# CBASS0_FW register map
Vendor: Texas Instruments
Peripheral module from a debugger description file (folder am243x).
Registers are 32-bit, read-write, reset 0x0 unless marked. A register's access mark holds for its fields unless they carry their own. Offsets are as the file gives them; lines under a group give offsets from that group; [hi:lo] are bit positions; {n}, {i} and the like mark numbered series; 'fields as' and 'values as' point back to an identical list; <NAME> marks a mode.

## CBASS0_FW
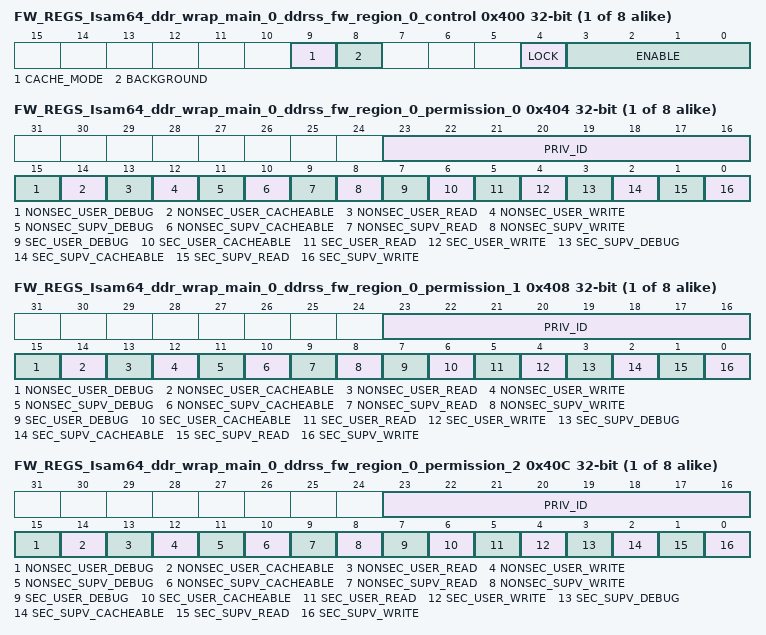
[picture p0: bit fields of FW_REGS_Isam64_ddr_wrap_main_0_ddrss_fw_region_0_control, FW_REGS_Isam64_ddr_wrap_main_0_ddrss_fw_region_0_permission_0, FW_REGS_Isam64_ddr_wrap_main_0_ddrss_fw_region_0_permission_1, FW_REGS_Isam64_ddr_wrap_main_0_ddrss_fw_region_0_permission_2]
{0x400+0x20*i} FW_REGS_Isam64_ddr_wrap_main_0_ddrss_fw_region_{i}_control access not given (i=0..7) — The FW Region {i} Control Register defines the control fields for the slave Isam64_ddr_wrap_main_0.ddrss region {i} firewall.
  [9] CACHE_MODE rw — Cache mode for region. Set to 1 to check cache permissions. Set to 0 to ignore cache permissions.
  [8] BACKGROUND rw — Background enable for region. There can be 1 backgroun region per FW and foreground regions can have overlapping addresses only with the background region.
  [4] LOCK — Lock region. Once set region values cannot be modified. (access R/W1TS)
  [3:0] ENABLE rw — Enable region. A value of 0xA enables, others disable.
{0x404+0x20*i} FW_REGS_Isam64_ddr_wrap_main_0_ddrss_fw_region_{i}_permission_0 (i=0..7) — The FW Region {i} Permission 0 Register defines the permissions for the slave Isam64_ddr_wrap_main_0.ddrss region {i} firewall.
  [23:16] PRIV_ID — Allowed privid.
  [15] NONSEC_USER_DEBUG — Non-secure user debug allowed.
  [14] NONSEC_USER_CACHEABLE — Non-secure user cacheable allowed.
  [13] NONSEC_USER_READ — Non-secure user read allowed.
  [12] NONSEC_USER_WRITE — Non-secure user write allowed.
  [11] NONSEC_SUPV_DEBUG — Non-secure supervisor debug allowed.
  [10] NONSEC_SUPV_CACHEABLE — Non-secure supervisor cacheable allowed.
  [9] NONSEC_SUPV_READ — Non-secure supervisor read allowed.
  [8] NONSEC_SUPV_WRITE — Non-secure supervisor write allowed.
  [7] SEC_USER_DEBUG — Secure user debug allowed.
  [6] SEC_USER_CACHEABLE — Secure user cacheable allowed.
  [5] SEC_USER_READ — Secure user read allowed.
  [4] SEC_USER_WRITE — Secure user write allowed.
  [3] SEC_SUPV_DEBUG — Secure supervisor debug allowed.
  [2] SEC_SUPV_CACHEABLE — Secure supervisor cacheable allowed.
  [1] SEC_SUPV_READ — Secure supervisor read allowed.
  [0] SEC_SUPV_WRITE — Secure supervisor write allowed.
{0x408+0x20*i} FW_REGS_Isam64_ddr_wrap_main_0_ddrss_fw_region_{i}_permission_1 (i=0..7) — The FW Region {i} Permission 1 Register defines the permissions for the slave Isam64_ddr_wrap_main_0.ddrss region {i} firewall.
  fields as FW_REGS_Isam64_ddr_wrap_main_0_ddrss_fw_region_0_permission_0
{0x40C+0x20*i} FW_REGS_Isam64_ddr_wrap_main_0_ddrss_fw_region_{i}_permission_2 (i=0..7) — The FW Region {i} Permission 2 Register defines the permissions for the slave Isam64_ddr_wrap_main_0.ddrss region {i} firewall.
  fields as FW_REGS_Isam64_ddr_wrap_main_0_ddrss_fw_region_0_permission_0
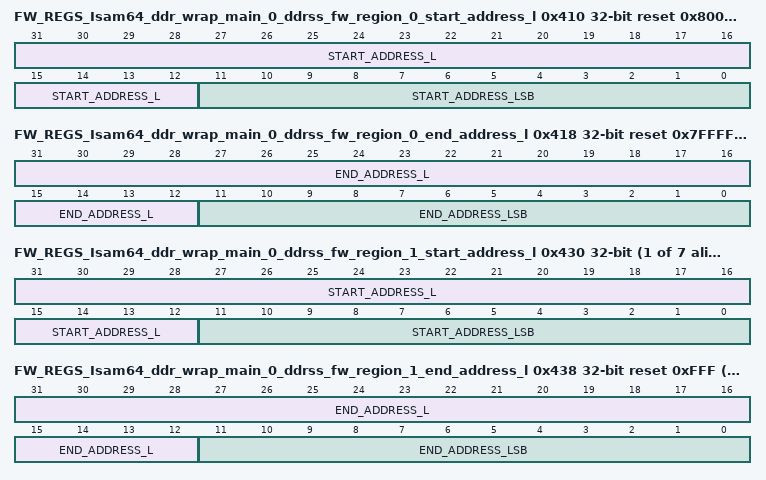
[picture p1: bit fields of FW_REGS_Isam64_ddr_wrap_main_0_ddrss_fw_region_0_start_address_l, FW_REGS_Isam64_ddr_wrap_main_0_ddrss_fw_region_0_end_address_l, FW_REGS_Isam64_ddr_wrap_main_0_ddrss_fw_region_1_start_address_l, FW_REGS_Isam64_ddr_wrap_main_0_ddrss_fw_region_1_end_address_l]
0x410 FW_REGS_Isam64_ddr_wrap_main_0_ddrss_fw_region_0_start_address_l access per field reset 0x80000000 — The FW Region 0 Start Address Low Register defines the start address bits 31 to 0 for the slave Isam64_ddr_wrap_main_0.ddrss region 0 firewall.
  [31:12] START_ADDRESS_L rw — Start address bits 31 to 12. Lowest 12 bits are forced to 0 as address must be 4KB aligned.
  [11:0] START_ADDRESS_LSB ro — Start address bits 11 to 0 are forced to 0 as address must be 4KB aligned.
{0x414+0x20*i} FW_REGS_Isam64_ddr_wrap_main_0_ddrss_fw_region_{i}_start_address_h (i=0..7) — The FW Region {i} Start Address High Register defines the start address bits 47 to 32 for the slave Isam64_ddr_wrap_main_0.ddrss region {i} firewall.
  [15:0] START_ADDRESS_H — Start address bits 47 to 32.
0x418 FW_REGS_Isam64_ddr_wrap_main_0_ddrss_fw_region_0_end_address_l access per field reset 0x7FFFFFFF — The FW Region 0 End Address Low Register defines the end address bits 31 to 0 to include for the slave Isam64_ddr_wrap_main_0.ddrss region 0 firewall.
  [31:12] END_ADDRESS_L rw — End address bits 31 to 12 to include in the match. Lowest 12 bits are forced to 1s as address must be 4KB aligned.
  [11:0] END_ADDRESS_LSB ro — End address bits 11 to 0 are forced to 1s as address must be 4KB aligned minus 1.
0x41C FW_REGS_Isam64_ddr_wrap_main_0_ddrss_fw_region_0_end_address_h reset 0x2 — The FW Region 0 End Address High Register defines the end address bits 47 to 32 to include for the slave Isam64_ddr_wrap_main_0.ddrss region 0 firewall.
  [15:0] END_ADDRESS_H — End address bits 47 to 32 to include in the match.
{0x410+0x20*i} FW_REGS_Isam64_ddr_wrap_main_0_ddrss_fw_region_{i}_start_address_l access per field (i=1..7) — The FW Region {i} Start Address Low Register defines the start address bits 31 to 0 for the slave Isam64_ddr_wrap_main_0.ddrss region {i} firewall.
  fields as FW_REGS_Isam64_ddr_wrap_main_0_ddrss_fw_region_0_start_address_l
{0x418+0x20*i} FW_REGS_Isam64_ddr_wrap_main_0_ddrss_fw_region_{i}_end_address_l access per field reset 0xFFF (i=1..7) — The FW Region {i} End Address Low Register defines the end address bits 31 to 0 to include for the slave Isam64_ddr_wrap_main_0.ddrss region {i} firewall.
  fields as FW_REGS_Isam64_ddr_wrap_main_0_ddrss_fw_region_0_end_address_l
{0x41C+0x20*i} FW_REGS_Isam64_ddr_wrap_main_0_ddrss_fw_region_{i}_end_address_h (i=1..7) — The FW Region {i} End Address High Register defines the end address bits 47 to 32 to include for the slave Isam64_ddr_wrap_main_0.ddrss region {i} firewall.
  fields as FW_REGS_Isam64_ddr_wrap_main_0_ddrss_fw_region_0_end_address_h
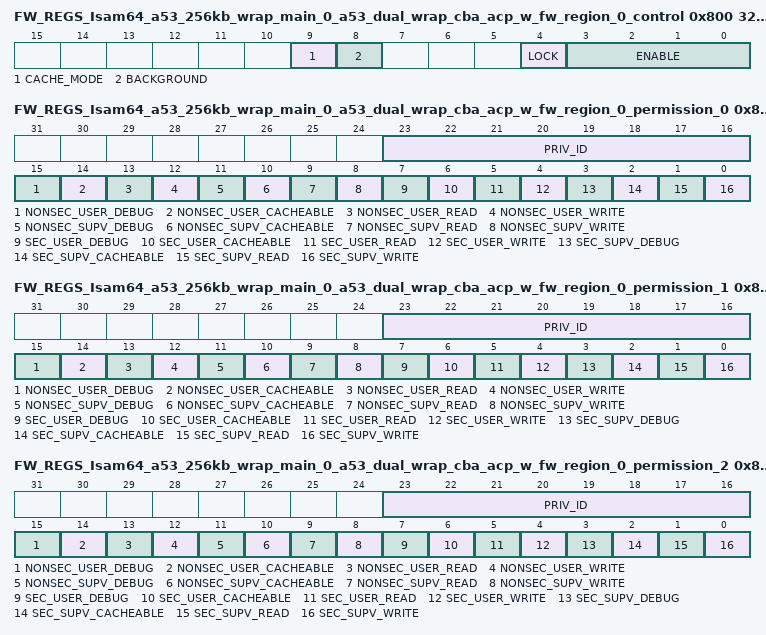
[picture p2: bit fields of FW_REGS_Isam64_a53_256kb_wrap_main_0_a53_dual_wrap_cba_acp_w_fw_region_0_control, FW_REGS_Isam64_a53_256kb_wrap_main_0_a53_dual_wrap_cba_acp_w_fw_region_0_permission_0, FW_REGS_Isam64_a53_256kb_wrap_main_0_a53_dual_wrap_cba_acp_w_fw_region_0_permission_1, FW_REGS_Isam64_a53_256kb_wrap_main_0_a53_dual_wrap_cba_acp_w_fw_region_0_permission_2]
{0x800+0x20*i} FW_REGS_Isam64_a53_256kb_wrap_main_0_a53_dual_wrap_cba_acp_w_fw_region_{i}_control access not given (i=0..7) — The FW Region {i} Control Register defines the control fields for the slave Isam64_a53_256kb_wrap_main_0.a53_dual_wrap_cba_acp_w region {i} firewall.
  fields as FW_REGS_Isam64_ddr_wrap_main_0_ddrss_fw_region_0_control
{0x804+0x20*i} FW_REGS_Isam64_a53_256kb_wrap_main_0_a53_dual_wrap_cba_acp_w_fw_region_{i}_permission_0 (i=0..7) — The FW Region {i} Permission 0 Register defines the permissions for the slave Isam64_a53_256kb_wrap_main_0.a53_dual_wrap_cba_acp_w region {i} firewall.
  fields as FW_REGS_Isam64_ddr_wrap_main_0_ddrss_fw_region_0_permission_0
{0x808+0x20*i} FW_REGS_Isam64_a53_256kb_wrap_main_0_a53_dual_wrap_cba_acp_w_fw_region_{i}_permission_1 (i=0..7) — The FW Region {i} Permission 1 Register defines the permissions for the slave Isam64_a53_256kb_wrap_main_0.a53_dual_wrap_cba_acp_w region {i} firewall.
  fields as FW_REGS_Isam64_ddr_wrap_main_0_ddrss_fw_region_0_permission_0
{0x80C+0x20*i} FW_REGS_Isam64_a53_256kb_wrap_main_0_a53_dual_wrap_cba_acp_w_fw_region_{i}_permission_2 (i=0..7) — The FW Region {i} Permission 2 Register defines the permissions for the slave Isam64_a53_256kb_wrap_main_0.a53_dual_wrap_cba_acp_w region {i} firewall.
  fields as FW_REGS_Isam64_ddr_wrap_main_0_ddrss_fw_region_0_permission_0
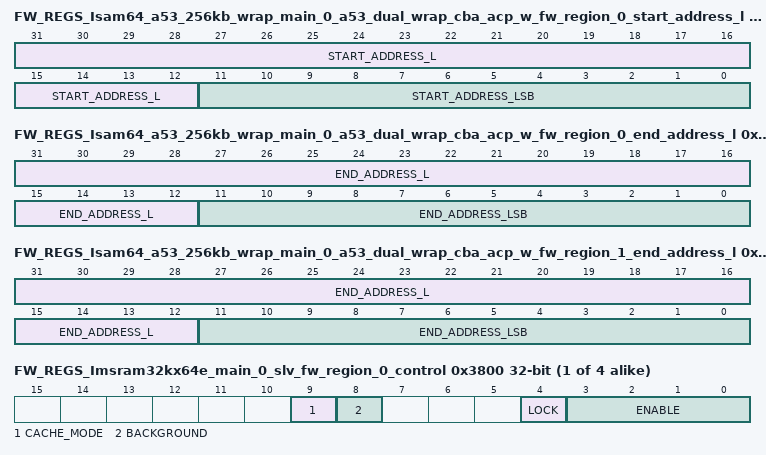
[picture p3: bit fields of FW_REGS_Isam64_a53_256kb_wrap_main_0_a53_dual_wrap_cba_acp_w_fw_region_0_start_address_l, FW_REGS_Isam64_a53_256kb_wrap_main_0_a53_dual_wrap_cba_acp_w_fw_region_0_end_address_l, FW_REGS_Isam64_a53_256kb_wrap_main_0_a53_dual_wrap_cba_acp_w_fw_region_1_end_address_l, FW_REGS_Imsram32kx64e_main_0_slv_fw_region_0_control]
{0x810+0x20*i} FW_REGS_Isam64_a53_256kb_wrap_main_0_a53_dual_wrap_cba_acp_w_fw_region_{i}_start_address_l access per field (i=0..7) — The FW Region {i} Start Address Low Register defines the start address bits 31 to 0 for the slave Isam64_a53_256kb_wrap_main_0.a53_dual_wrap_cba_acp_w region {i} firewall.
  fields as FW_REGS_Isam64_ddr_wrap_main_0_ddrss_fw_region_0_start_address_l
{0x814+0x20*i} FW_REGS_Isam64_a53_256kb_wrap_main_0_a53_dual_wrap_cba_acp_w_fw_region_{i}_start_address_h (i=0..7) — The FW Region {i} Start Address High Register defines the start address bits 47 to 32 for the slave Isam64_a53_256kb_wrap_main_0.a53_dual_wrap_cba_acp_w region {i} firewall.
  [15:0] START_ADDRESS_H — Start address bits 47 to 32.
0x818 FW_REGS_Isam64_a53_256kb_wrap_main_0_a53_dual_wrap_cba_acp_w_fw_region_0_end_address_l access per field reset 0xFFFFFFFF — The FW Region 0 End Address Low Register defines the end address bits 31 to 0 to include for the slave Isam64_a53_256kb_wrap_main_0.a53_dual_wrap_cba_acp_w region 0 firewall.
  fields as FW_REGS_Isam64_ddr_wrap_main_0_ddrss_fw_region_0_end_address_l
0x81C FW_REGS_Isam64_a53_256kb_wrap_main_0_a53_dual_wrap_cba_acp_w_fw_region_0_end_address_h reset 0xF — The FW Region 0 End Address High Register defines the end address bits 47 to 32 to include for the slave Isam64_a53_256kb_wrap_main_0.a53_dual_wrap_cba_acp_w region 0 firewall.
  fields as FW_REGS_Isam64_ddr_wrap_main_0_ddrss_fw_region_0_end_address_h
{0x818+0x20*i} FW_REGS_Isam64_a53_256kb_wrap_main_0_a53_dual_wrap_cba_acp_w_fw_region_{i}_end_address_l access per field reset 0xFFF (i=1..7) — The FW Region {i} End Address Low Register defines the end address bits 31 to 0 to include for the slave Isam64_a53_256kb_wrap_main_0.a53_dual_wrap_cba_acp_w region {i} firewall.
  fields as FW_REGS_Isam64_ddr_wrap_main_0_ddrss_fw_region_0_end_address_l
{0x81C+0x20*i} FW_REGS_Isam64_a53_256kb_wrap_main_0_a53_dual_wrap_cba_acp_w_fw_region_{i}_end_address_h (i=1..7) — The FW Region {i} End Address High Register defines the end address bits 47 to 32 to include for the slave Isam64_a53_256kb_wrap_main_0.a53_dual_wrap_cba_acp_w region {i} firewall.
  fields as FW_REGS_Isam64_ddr_wrap_main_0_ddrss_fw_region_0_end_address_h
{0x3800+0x20*i} FW_REGS_Imsram32kx64e_main_0_slv_fw_region_{i}_control access not given (i=0..3) — The FW Region {i} Control Register defines the control fields for the slave Imsram32kx64e_main_0.slv region {i} firewall.
  fields as FW_REGS_Isam64_ddr_wrap_main_0_ddrss_fw_region_0_control
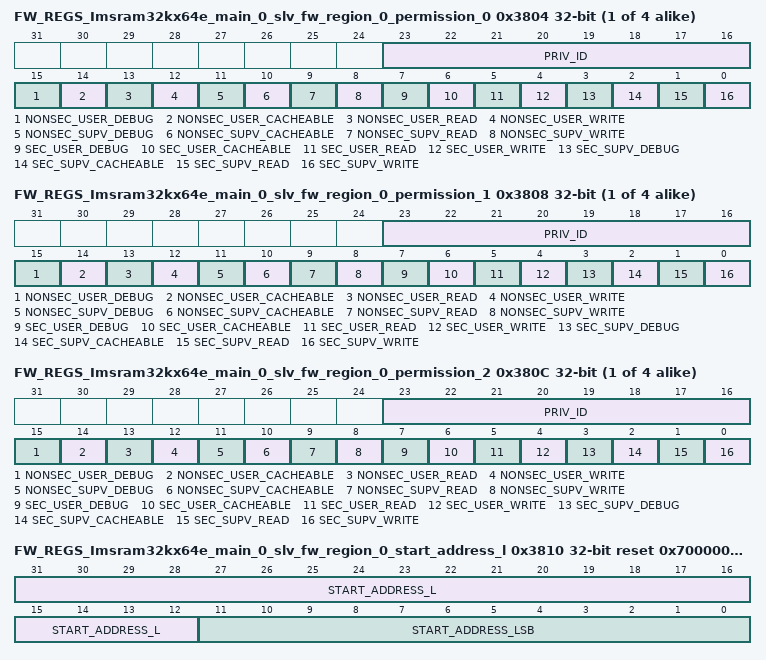
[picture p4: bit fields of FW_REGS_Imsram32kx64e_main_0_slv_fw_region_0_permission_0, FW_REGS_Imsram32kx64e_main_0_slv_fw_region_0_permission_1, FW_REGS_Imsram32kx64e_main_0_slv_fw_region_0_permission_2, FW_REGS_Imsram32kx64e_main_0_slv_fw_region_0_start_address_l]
{0x3804+0x20*i} FW_REGS_Imsram32kx64e_main_0_slv_fw_region_{i}_permission_0 (i=0..3) — The FW Region {i} Permission 0 Register defines the permissions for the slave Imsram32kx64e_main_0.slv region {i} firewall.
  fields as FW_REGS_Isam64_ddr_wrap_main_0_ddrss_fw_region_0_permission_0
{0x3808+0x20*i} FW_REGS_Imsram32kx64e_main_0_slv_fw_region_{i}_permission_1 (i=0..3) — The FW Region {i} Permission 1 Register defines the permissions for the slave Imsram32kx64e_main_0.slv region {i} firewall.
  fields as FW_REGS_Isam64_ddr_wrap_main_0_ddrss_fw_region_0_permission_0
{0x380C+0x20*i} FW_REGS_Imsram32kx64e_main_0_slv_fw_region_{i}_permission_2 (i=0..3) — The FW Region {i} Permission 2 Register defines the permissions for the slave Imsram32kx64e_main_0.slv region {i} firewall.
  fields as FW_REGS_Isam64_ddr_wrap_main_0_ddrss_fw_region_0_permission_0
0x3810 FW_REGS_Imsram32kx64e_main_0_slv_fw_region_0_start_address_l access per field reset 0x70000000 — The FW Region 0 Start Address Low Register defines the start address bits 31 to 0 for the slave Imsram32kx64e_main_0.slv region 0 firewall.
  fields as FW_REGS_Isam64_ddr_wrap_main_0_ddrss_fw_region_0_start_address_l
{0x3814+0x20*i} FW_REGS_Imsram32kx64e_main_0_slv_fw_region_{i}_start_address_h (i=0..3) — The FW Region {i} Start Address High Register defines the start address bits 47 to 32 for the slave Imsram32kx64e_main_0.slv region {i} firewall.
  [15:0] START_ADDRESS_H — Start address bits 47 to 32.
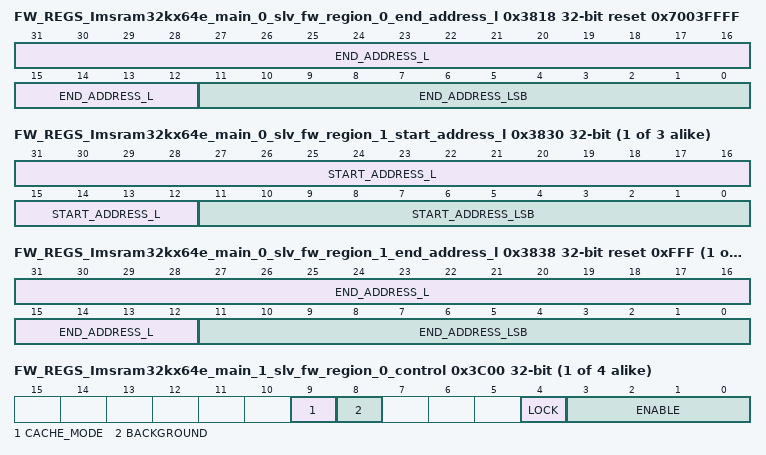
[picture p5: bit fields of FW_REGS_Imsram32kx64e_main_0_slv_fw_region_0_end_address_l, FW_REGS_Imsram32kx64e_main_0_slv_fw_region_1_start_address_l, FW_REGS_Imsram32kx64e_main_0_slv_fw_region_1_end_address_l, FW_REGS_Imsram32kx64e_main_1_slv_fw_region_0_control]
0x3818 FW_REGS_Imsram32kx64e_main_0_slv_fw_region_0_end_address_l access per field reset 0x7003FFFF — The FW Region 0 End Address Low Register defines the end address bits 31 to 0 to include for the slave Imsram32kx64e_main_0.slv region 0 firewall.
  fields as FW_REGS_Isam64_ddr_wrap_main_0_ddrss_fw_region_0_end_address_l
{0x381C+0x20*i} FW_REGS_Imsram32kx64e_main_0_slv_fw_region_{i}_end_address_h (i=0..3) — The FW Region {i} End Address High Register defines the end address bits 47 to 32 to include for the slave Imsram32kx64e_main_0.slv region {i} firewall.
  fields as FW_REGS_Isam64_ddr_wrap_main_0_ddrss_fw_region_0_end_address_h
{0x3810+0x20*i} FW_REGS_Imsram32kx64e_main_0_slv_fw_region_{i}_start_address_l access per field (i=1..3) — The FW Region {i} Start Address Low Register defines the start address bits 31 to 0 for the slave Imsram32kx64e_main_0.slv region {i} firewall.
  fields as FW_REGS_Isam64_ddr_wrap_main_0_ddrss_fw_region_0_start_address_l
{0x3818+0x20*i} FW_REGS_Imsram32kx64e_main_0_slv_fw_region_{i}_end_address_l access per field reset 0xFFF (i=1..3) — The FW Region {i} End Address Low Register defines the end address bits 31 to 0 to include for the slave Imsram32kx64e_main_0.slv region {i} firewall.
  fields as FW_REGS_Isam64_ddr_wrap_main_0_ddrss_fw_region_0_end_address_l
{0x3C00+0x20*i} FW_REGS_Imsram32kx64e_main_1_slv_fw_region_{i}_control access not given (i=0..3) — The FW Region {i} Control Register defines the control fields for the slave Imsram32kx64e_main_1.slv region {i} firewall.
  fields as FW_REGS_Isam64_ddr_wrap_main_0_ddrss_fw_region_0_control
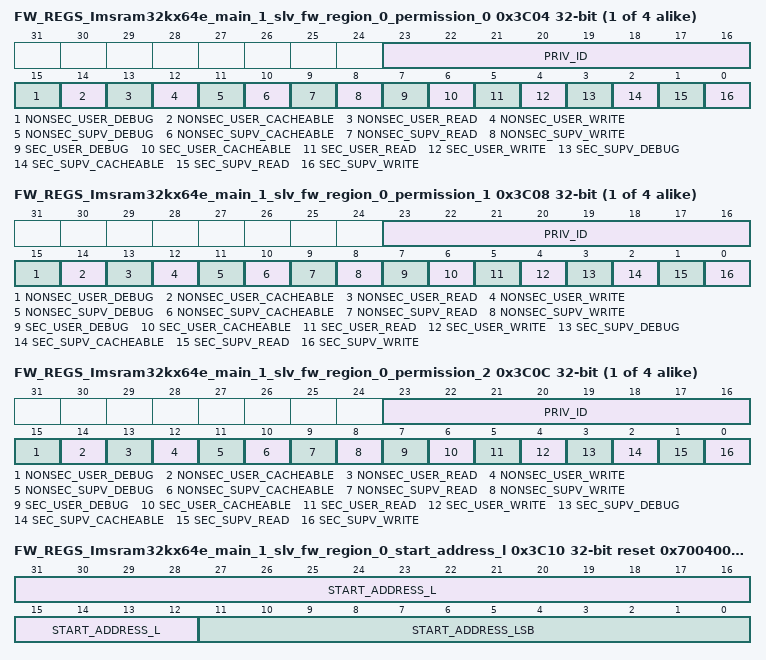
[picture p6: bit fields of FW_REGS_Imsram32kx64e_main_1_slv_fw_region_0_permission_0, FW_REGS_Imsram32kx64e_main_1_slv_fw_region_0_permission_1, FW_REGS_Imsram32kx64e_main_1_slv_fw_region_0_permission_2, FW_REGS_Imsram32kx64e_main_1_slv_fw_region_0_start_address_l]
{0x3C04+0x20*i} FW_REGS_Imsram32kx64e_main_1_slv_fw_region_{i}_permission_0 (i=0..3) — The FW Region {i} Permission 0 Register defines the permissions for the slave Imsram32kx64e_main_1.slv region {i} firewall.
  fields as FW_REGS_Isam64_ddr_wrap_main_0_ddrss_fw_region_0_permission_0
{0x3C08+0x20*i} FW_REGS_Imsram32kx64e_main_1_slv_fw_region_{i}_permission_1 (i=0..3) — The FW Region {i} Permission 1 Register defines the permissions for the slave Imsram32kx64e_main_1.slv region {i} firewall.
  fields as FW_REGS_Isam64_ddr_wrap_main_0_ddrss_fw_region_0_permission_0
{0x3C0C+0x20*i} FW_REGS_Imsram32kx64e_main_1_slv_fw_region_{i}_permission_2 (i=0..3) — The FW Region {i} Permission 2 Register defines the permissions for the slave Imsram32kx64e_main_1.slv region {i} firewall.
  fields as FW_REGS_Isam64_ddr_wrap_main_0_ddrss_fw_region_0_permission_0
0x3C10 FW_REGS_Imsram32kx64e_main_1_slv_fw_region_0_start_address_l access per field reset 0x70040000 — The FW Region 0 Start Address Low Register defines the start address bits 31 to 0 for the slave Imsram32kx64e_main_1.slv region 0 firewall.
  fields as FW_REGS_Isam64_ddr_wrap_main_0_ddrss_fw_region_0_start_address_l
{0x3C14+0x20*i} FW_REGS_Imsram32kx64e_main_1_slv_fw_region_{i}_start_address_h (i=0..3) — The FW Region {i} Start Address High Register defines the start address bits 47 to 32 for the slave Imsram32kx64e_main_1.slv region {i} firewall.
  [15:0] START_ADDRESS_H — Start address bits 47 to 32.
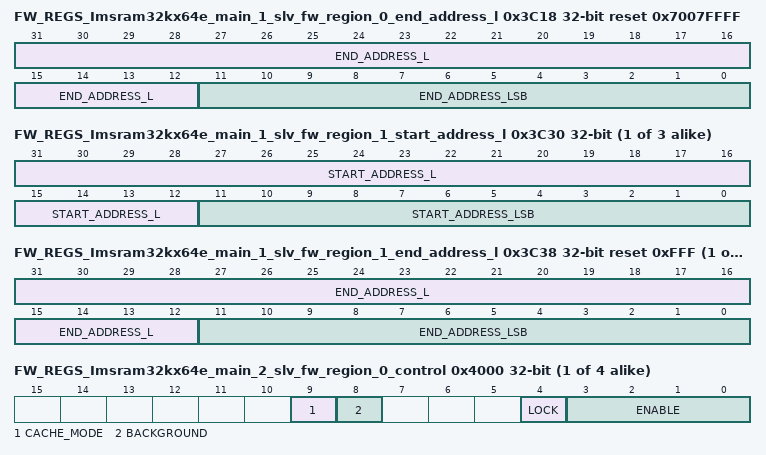
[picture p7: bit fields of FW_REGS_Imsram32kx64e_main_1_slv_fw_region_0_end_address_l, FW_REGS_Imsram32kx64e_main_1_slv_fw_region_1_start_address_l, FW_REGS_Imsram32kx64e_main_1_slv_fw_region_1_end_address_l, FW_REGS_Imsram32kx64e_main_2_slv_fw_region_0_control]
0x3C18 FW_REGS_Imsram32kx64e_main_1_slv_fw_region_0_end_address_l access per field reset 0x7007FFFF — The FW Region 0 End Address Low Register defines the end address bits 31 to 0 to include for the slave Imsram32kx64e_main_1.slv region 0 firewall.
  fields as FW_REGS_Isam64_ddr_wrap_main_0_ddrss_fw_region_0_end_address_l
{0x3C1C+0x20*i} FW_REGS_Imsram32kx64e_main_1_slv_fw_region_{i}_end_address_h (i=0..3) — The FW Region {i} End Address High Register defines the end address bits 47 to 32 to include for the slave Imsram32kx64e_main_1.slv region {i} firewall.
  fields as FW_REGS_Isam64_ddr_wrap_main_0_ddrss_fw_region_0_end_address_h
{0x3C10+0x20*i} FW_REGS_Imsram32kx64e_main_1_slv_fw_region_{i}_start_address_l access per field (i=1..3) — The FW Region {i} Start Address Low Register defines the start address bits 31 to 0 for the slave Imsram32kx64e_main_1.slv region {i} firewall.
  fields as FW_REGS_Isam64_ddr_wrap_main_0_ddrss_fw_region_0_start_address_l
{0x3C18+0x20*i} FW_REGS_Imsram32kx64e_main_1_slv_fw_region_{i}_end_address_l access per field reset 0xFFF (i=1..3) — The FW Region {i} End Address Low Register defines the end address bits 31 to 0 to include for the slave Imsram32kx64e_main_1.slv region {i} firewall.
  fields as FW_REGS_Isam64_ddr_wrap_main_0_ddrss_fw_region_0_end_address_l
{0x4000+0x20*i} FW_REGS_Imsram32kx64e_main_2_slv_fw_region_{i}_control access not given (i=0..3) — The FW Region {i} Control Register defines the control fields for the slave Imsram32kx64e_main_2.slv region {i} firewall.
  fields as FW_REGS_Isam64_ddr_wrap_main_0_ddrss_fw_region_0_control
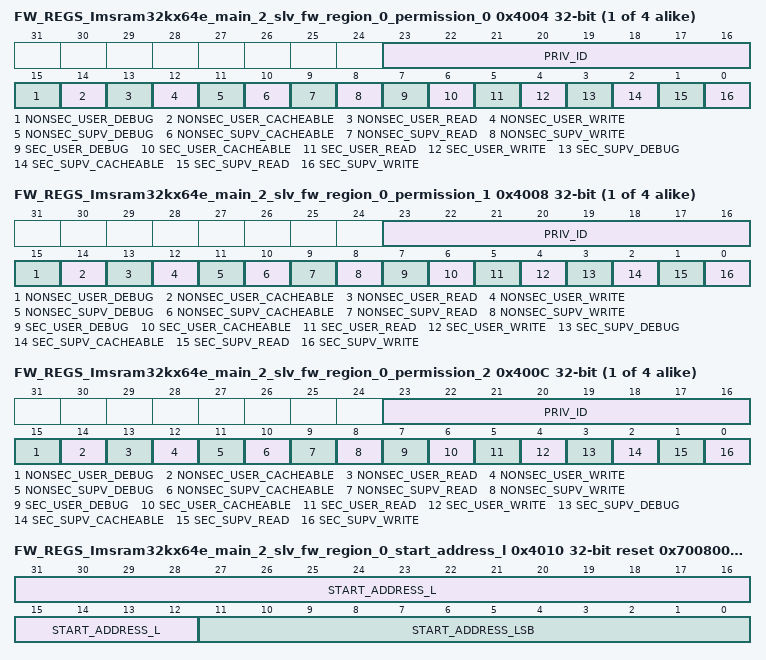
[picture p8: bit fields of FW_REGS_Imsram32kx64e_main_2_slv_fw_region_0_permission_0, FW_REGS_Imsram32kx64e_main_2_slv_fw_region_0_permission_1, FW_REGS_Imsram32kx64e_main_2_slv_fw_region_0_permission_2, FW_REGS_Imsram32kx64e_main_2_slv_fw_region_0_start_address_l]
{0x4004+0x20*i} FW_REGS_Imsram32kx64e_main_2_slv_fw_region_{i}_permission_0 (i=0..3) — The FW Region {i} Permission 0 Register defines the permissions for the slave Imsram32kx64e_main_2.slv region {i} firewall.
  fields as FW_REGS_Isam64_ddr_wrap_main_0_ddrss_fw_region_0_permission_0
{0x4008+0x20*i} FW_REGS_Imsram32kx64e_main_2_slv_fw_region_{i}_permission_1 (i=0..3) — The FW Region {i} Permission 1 Register defines the permissions for the slave Imsram32kx64e_main_2.slv region {i} firewall.
  fields as FW_REGS_Isam64_ddr_wrap_main_0_ddrss_fw_region_0_permission_0
{0x400C+0x20*i} FW_REGS_Imsram32kx64e_main_2_slv_fw_region_{i}_permission_2 (i=0..3) — The FW Region {i} Permission 2 Register defines the permissions for the slave Imsram32kx64e_main_2.slv region {i} firewall.
  fields as FW_REGS_Isam64_ddr_wrap_main_0_ddrss_fw_region_0_permission_0
0x4010 FW_REGS_Imsram32kx64e_main_2_slv_fw_region_0_start_address_l access per field reset 0x70080000 — The FW Region 0 Start Address Low Register defines the start address bits 31 to 0 for the slave Imsram32kx64e_main_2.slv region 0 firewall.
  fields as FW_REGS_Isam64_ddr_wrap_main_0_ddrss_fw_region_0_start_address_l
{0x4014+0x20*i} FW_REGS_Imsram32kx64e_main_2_slv_fw_region_{i}_start_address_h (i=0..3) — The FW Region {i} Start Address High Register defines the start address bits 47 to 32 for the slave Imsram32kx64e_main_2.slv region {i} firewall.
  [15:0] START_ADDRESS_H — Start address bits 47 to 32.
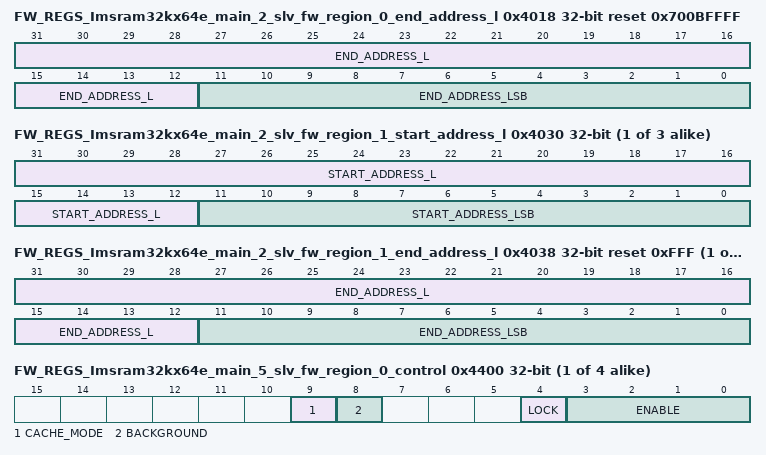
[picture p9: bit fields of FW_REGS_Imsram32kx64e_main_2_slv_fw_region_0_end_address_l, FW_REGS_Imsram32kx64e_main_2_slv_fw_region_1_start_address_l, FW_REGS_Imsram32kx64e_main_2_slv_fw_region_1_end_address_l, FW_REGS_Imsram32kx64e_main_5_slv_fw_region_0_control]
0x4018 FW_REGS_Imsram32kx64e_main_2_slv_fw_region_0_end_address_l access per field reset 0x700BFFFF — The FW Region 0 End Address Low Register defines the end address bits 31 to 0 to include for the slave Imsram32kx64e_main_2.slv region 0 firewall.
  fields as FW_REGS_Isam64_ddr_wrap_main_0_ddrss_fw_region_0_end_address_l
{0x401C+0x20*i} FW_REGS_Imsram32kx64e_main_2_slv_fw_region_{i}_end_address_h (i=0..3) — The FW Region {i} End Address High Register defines the end address bits 47 to 32 to include for the slave Imsram32kx64e_main_2.slv region {i} firewall.
  fields as FW_REGS_Isam64_ddr_wrap_main_0_ddrss_fw_region_0_end_address_h
{0x4010+0x20*i} FW_REGS_Imsram32kx64e_main_2_slv_fw_region_{i}_start_address_l access per field (i=1..3) — The FW Region {i} Start Address Low Register defines the start address bits 31 to 0 for the slave Imsram32kx64e_main_2.slv region {i} firewall.
  fields as FW_REGS_Isam64_ddr_wrap_main_0_ddrss_fw_region_0_start_address_l
{0x4018+0x20*i} FW_REGS_Imsram32kx64e_main_2_slv_fw_region_{i}_end_address_l access per field reset 0xFFF (i=1..3) — The FW Region {i} End Address Low Register defines the end address bits 31 to 0 to include for the slave Imsram32kx64e_main_2.slv region {i} firewall.
  fields as FW_REGS_Isam64_ddr_wrap_main_0_ddrss_fw_region_0_end_address_l
{0x4400+0x20*i} FW_REGS_Imsram32kx64e_main_5_slv_fw_region_{i}_control access not given (i=0..3) — The FW Region {i} Control Register defines the control fields for the slave Imsram32kx64e_main_5.slv region {i} firewall.
  fields as FW_REGS_Isam64_ddr_wrap_main_0_ddrss_fw_region_0_control
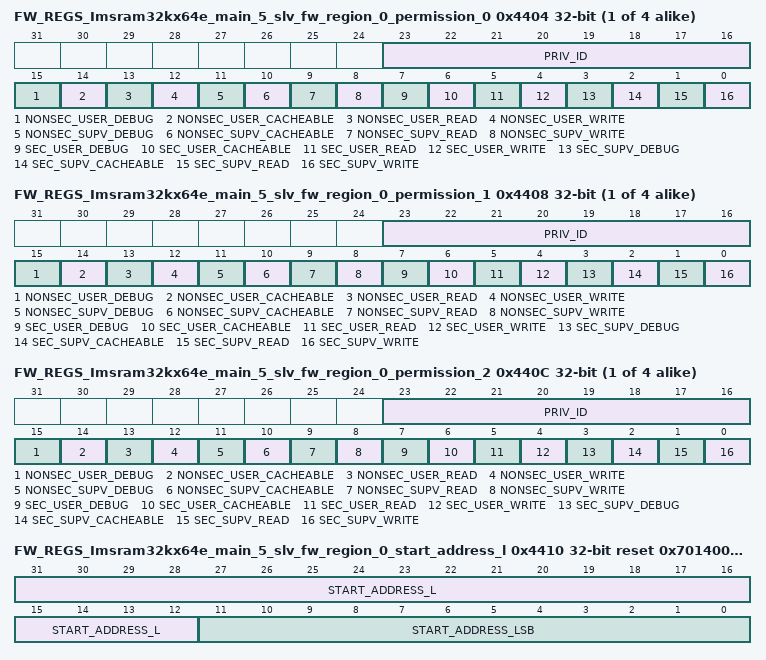
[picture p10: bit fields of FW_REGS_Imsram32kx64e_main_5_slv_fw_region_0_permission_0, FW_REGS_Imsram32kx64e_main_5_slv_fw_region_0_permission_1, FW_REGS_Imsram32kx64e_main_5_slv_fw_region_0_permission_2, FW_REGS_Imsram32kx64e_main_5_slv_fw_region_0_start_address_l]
{0x4404+0x20*i} FW_REGS_Imsram32kx64e_main_5_slv_fw_region_{i}_permission_0 (i=0..3) — The FW Region {i} Permission 0 Register defines the permissions for the slave Imsram32kx64e_main_5.slv region {i} firewall.
  fields as FW_REGS_Isam64_ddr_wrap_main_0_ddrss_fw_region_0_permission_0
{0x4408+0x20*i} FW_REGS_Imsram32kx64e_main_5_slv_fw_region_{i}_permission_1 (i=0..3) — The FW Region {i} Permission 1 Register defines the permissions for the slave Imsram32kx64e_main_5.slv region {i} firewall.
  fields as FW_REGS_Isam64_ddr_wrap_main_0_ddrss_fw_region_0_permission_0
{0x440C+0x20*i} FW_REGS_Imsram32kx64e_main_5_slv_fw_region_{i}_permission_2 (i=0..3) — The FW Region {i} Permission 2 Register defines the permissions for the slave Imsram32kx64e_main_5.slv region {i} firewall.
  fields as FW_REGS_Isam64_ddr_wrap_main_0_ddrss_fw_region_0_permission_0
0x4410 FW_REGS_Imsram32kx64e_main_5_slv_fw_region_0_start_address_l access per field reset 0x70140000 — The FW Region 0 Start Address Low Register defines the start address bits 31 to 0 for the slave Imsram32kx64e_main_5.slv region 0 firewall.
  fields as FW_REGS_Isam64_ddr_wrap_main_0_ddrss_fw_region_0_start_address_l
{0x4414+0x20*i} FW_REGS_Imsram32kx64e_main_5_slv_fw_region_{i}_start_address_h (i=0..3) — The FW Region {i} Start Address High Register defines the start address bits 47 to 32 for the slave Imsram32kx64e_main_5.slv region {i} firewall.
  [15:0] START_ADDRESS_H — Start address bits 47 to 32.
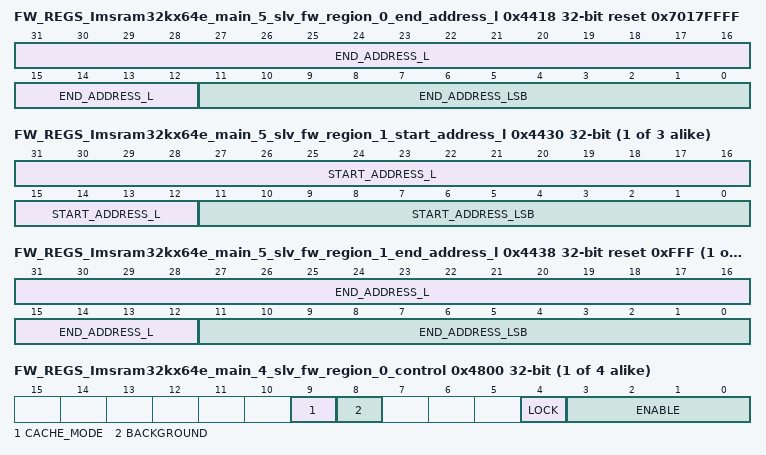
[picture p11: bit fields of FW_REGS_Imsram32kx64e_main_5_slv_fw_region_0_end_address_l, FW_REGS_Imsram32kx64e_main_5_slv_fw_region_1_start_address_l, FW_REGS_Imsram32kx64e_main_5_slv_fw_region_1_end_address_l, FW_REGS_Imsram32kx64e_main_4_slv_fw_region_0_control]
0x4418 FW_REGS_Imsram32kx64e_main_5_slv_fw_region_0_end_address_l access per field reset 0x7017FFFF — The FW Region 0 End Address Low Register defines the end address bits 31 to 0 to include for the slave Imsram32kx64e_main_5.slv region 0 firewall.
  fields as FW_REGS_Isam64_ddr_wrap_main_0_ddrss_fw_region_0_end_address_l
{0x441C+0x20*i} FW_REGS_Imsram32kx64e_main_5_slv_fw_region_{i}_end_address_h (i=0..3) — The FW Region {i} End Address High Register defines the end address bits 47 to 32 to include for the slave Imsram32kx64e_main_5.slv region {i} firewall.
  fields as FW_REGS_Isam64_ddr_wrap_main_0_ddrss_fw_region_0_end_address_h
{0x4410+0x20*i} FW_REGS_Imsram32kx64e_main_5_slv_fw_region_{i}_start_address_l access per field (i=1..3) — The FW Region {i} Start Address Low Register defines the start address bits 31 to 0 for the slave Imsram32kx64e_main_5.slv region {i} firewall.
  fields as FW_REGS_Isam64_ddr_wrap_main_0_ddrss_fw_region_0_start_address_l
{0x4418+0x20*i} FW_REGS_Imsram32kx64e_main_5_slv_fw_region_{i}_end_address_l access per field reset 0xFFF (i=1..3) — The FW Region {i} End Address Low Register defines the end address bits 31 to 0 to include for the slave Imsram32kx64e_main_5.slv region {i} firewall.
  fields as FW_REGS_Isam64_ddr_wrap_main_0_ddrss_fw_region_0_end_address_l
{0x4800+0x20*i} FW_REGS_Imsram32kx64e_main_4_slv_fw_region_{i}_control access not given (i=0..3) — The FW Region {i} Control Register defines the control fields for the slave Imsram32kx64e_main_4.slv region {i} firewall.
  fields as FW_REGS_Isam64_ddr_wrap_main_0_ddrss_fw_region_0_control
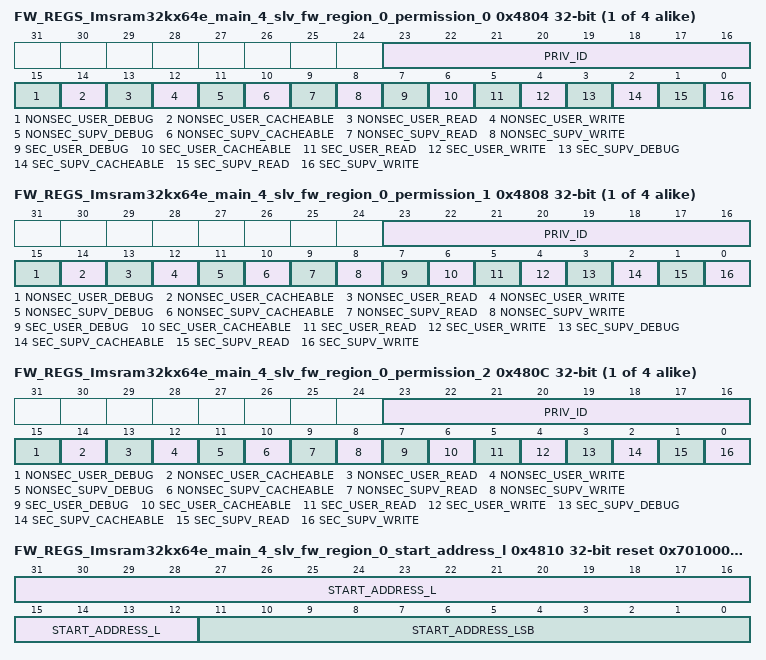
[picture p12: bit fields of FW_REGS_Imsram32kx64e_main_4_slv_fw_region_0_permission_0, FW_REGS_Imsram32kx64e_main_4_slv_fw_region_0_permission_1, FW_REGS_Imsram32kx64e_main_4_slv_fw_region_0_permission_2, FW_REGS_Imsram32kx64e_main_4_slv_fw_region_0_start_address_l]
{0x4804+0x20*i} FW_REGS_Imsram32kx64e_main_4_slv_fw_region_{i}_permission_0 (i=0..3) — The FW Region {i} Permission 0 Register defines the permissions for the slave Imsram32kx64e_main_4.slv region {i} firewall.
  fields as FW_REGS_Isam64_ddr_wrap_main_0_ddrss_fw_region_0_permission_0
{0x4808+0x20*i} FW_REGS_Imsram32kx64e_main_4_slv_fw_region_{i}_permission_1 (i=0..3) — The FW Region {i} Permission 1 Register defines the permissions for the slave Imsram32kx64e_main_4.slv region {i} firewall.
  fields as FW_REGS_Isam64_ddr_wrap_main_0_ddrss_fw_region_0_permission_0
{0x480C+0x20*i} FW_REGS_Imsram32kx64e_main_4_slv_fw_region_{i}_permission_2 (i=0..3) — The FW Region {i} Permission 2 Register defines the permissions for the slave Imsram32kx64e_main_4.slv region {i} firewall.
  fields as FW_REGS_Isam64_ddr_wrap_main_0_ddrss_fw_region_0_permission_0
0x4810 FW_REGS_Imsram32kx64e_main_4_slv_fw_region_0_start_address_l access per field reset 0x70100000 — The FW Region 0 Start Address Low Register defines the start address bits 31 to 0 for the slave Imsram32kx64e_main_4.slv region 0 firewall.
  fields as FW_REGS_Isam64_ddr_wrap_main_0_ddrss_fw_region_0_start_address_l
{0x4814+0x20*i} FW_REGS_Imsram32kx64e_main_4_slv_fw_region_{i}_start_address_h (i=0..3) — The FW Region {i} Start Address High Register defines the start address bits 47 to 32 for the slave Imsram32kx64e_main_4.slv region {i} firewall.
  [15:0] START_ADDRESS_H — Start address bits 47 to 32.
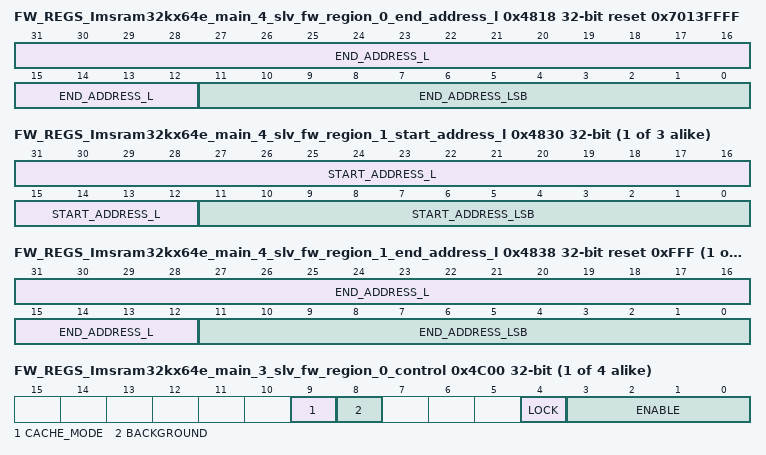
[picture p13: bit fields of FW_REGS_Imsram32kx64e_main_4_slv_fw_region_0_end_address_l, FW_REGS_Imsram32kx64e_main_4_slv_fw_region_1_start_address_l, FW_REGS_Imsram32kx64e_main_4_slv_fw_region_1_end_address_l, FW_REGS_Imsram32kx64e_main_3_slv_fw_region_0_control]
0x4818 FW_REGS_Imsram32kx64e_main_4_slv_fw_region_0_end_address_l access per field reset 0x7013FFFF — The FW Region 0 End Address Low Register defines the end address bits 31 to 0 to include for the slave Imsram32kx64e_main_4.slv region 0 firewall.
  fields as FW_REGS_Isam64_ddr_wrap_main_0_ddrss_fw_region_0_end_address_l
{0x481C+0x20*i} FW_REGS_Imsram32kx64e_main_4_slv_fw_region_{i}_end_address_h (i=0..3) — The FW Region {i} End Address High Register defines the end address bits 47 to 32 to include for the slave Imsram32kx64e_main_4.slv region {i} firewall.
  fields as FW_REGS_Isam64_ddr_wrap_main_0_ddrss_fw_region_0_end_address_h
{0x4810+0x20*i} FW_REGS_Imsram32kx64e_main_4_slv_fw_region_{i}_start_address_l access per field (i=1..3) — The FW Region {i} Start Address Low Register defines the start address bits 31 to 0 for the slave Imsram32kx64e_main_4.slv region {i} firewall.
  fields as FW_REGS_Isam64_ddr_wrap_main_0_ddrss_fw_region_0_start_address_l
{0x4818+0x20*i} FW_REGS_Imsram32kx64e_main_4_slv_fw_region_{i}_end_address_l access per field reset 0xFFF (i=1..3) — The FW Region {i} End Address Low Register defines the end address bits 31 to 0 to include for the slave Imsram32kx64e_main_4.slv region {i} firewall.
  fields as FW_REGS_Isam64_ddr_wrap_main_0_ddrss_fw_region_0_end_address_l
{0x4C00+0x20*i} FW_REGS_Imsram32kx64e_main_3_slv_fw_region_{i}_control access not given (i=0..3) — The FW Region {i} Control Register defines the control fields for the slave Imsram32kx64e_main_3.slv region {i} firewall.
  fields as FW_REGS_Isam64_ddr_wrap_main_0_ddrss_fw_region_0_control
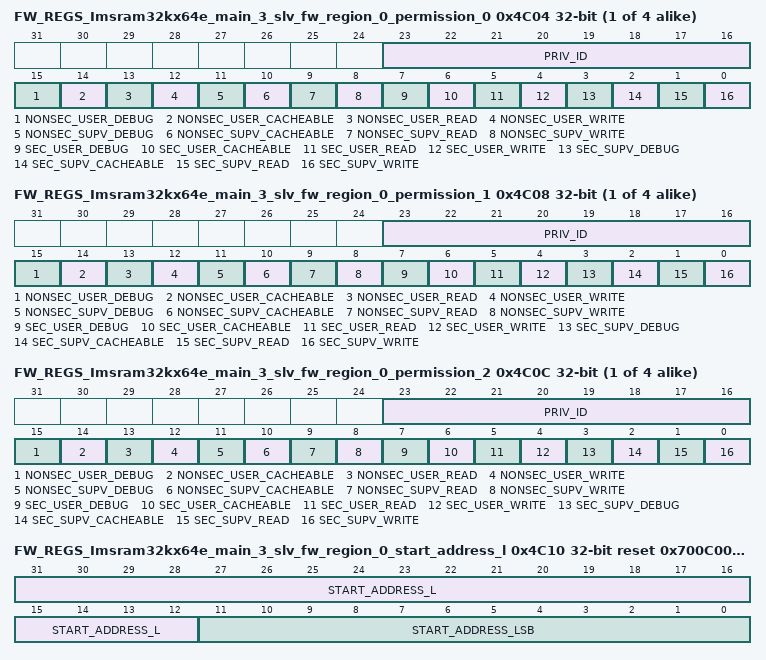
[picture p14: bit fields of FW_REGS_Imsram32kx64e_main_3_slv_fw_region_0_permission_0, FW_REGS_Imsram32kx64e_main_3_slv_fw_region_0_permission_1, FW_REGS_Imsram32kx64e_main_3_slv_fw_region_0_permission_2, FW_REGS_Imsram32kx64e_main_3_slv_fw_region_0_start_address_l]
{0x4C04+0x20*i} FW_REGS_Imsram32kx64e_main_3_slv_fw_region_{i}_permission_0 (i=0..3) — The FW Region {i} Permission 0 Register defines the permissions for the slave Imsram32kx64e_main_3.slv region {i} firewall.
  fields as FW_REGS_Isam64_ddr_wrap_main_0_ddrss_fw_region_0_permission_0
{0x4C08+0x20*i} FW_REGS_Imsram32kx64e_main_3_slv_fw_region_{i}_permission_1 (i=0..3) — The FW Region {i} Permission 1 Register defines the permissions for the slave Imsram32kx64e_main_3.slv region {i} firewall.
  fields as FW_REGS_Isam64_ddr_wrap_main_0_ddrss_fw_region_0_permission_0
{0x4C0C+0x20*i} FW_REGS_Imsram32kx64e_main_3_slv_fw_region_{i}_permission_2 (i=0..3) — The FW Region {i} Permission 2 Register defines the permissions for the slave Imsram32kx64e_main_3.slv region {i} firewall.
  fields as FW_REGS_Isam64_ddr_wrap_main_0_ddrss_fw_region_0_permission_0
0x4C10 FW_REGS_Imsram32kx64e_main_3_slv_fw_region_0_start_address_l access per field reset 0x700C0000 — The FW Region 0 Start Address Low Register defines the start address bits 31 to 0 for the slave Imsram32kx64e_main_3.slv region 0 firewall.
  fields as FW_REGS_Isam64_ddr_wrap_main_0_ddrss_fw_region_0_start_address_l
{0x4C14+0x20*i} FW_REGS_Imsram32kx64e_main_3_slv_fw_region_{i}_start_address_h (i=0..3) — The FW Region {i} Start Address High Register defines the start address bits 47 to 32 for the slave Imsram32kx64e_main_3.slv region {i} firewall.
  [15:0] START_ADDRESS_H — Start address bits 47 to 32.
0x4C18 FW_REGS_Imsram32kx64e_main_3_slv_fw_region_0_end_address_l access per field reset 0x700FFFFF — The FW Region 0 End Address Low Register defines the end address bits 31 to 0 to include for the slave Imsram32kx64e_main_3.slv region 0 firewall.
  fields as FW_REGS_Isam64_ddr_wrap_main_0_ddrss_fw_region_0_end_address_l
{0x4C1C+0x20*i} FW_REGS_Imsram32kx64e_main_3_slv_fw_region_{i}_end_address_h (i=0..3) — The FW Region {i} End Address High Register defines the end address bits 47 to 32 to include for the slave Imsram32kx64e_main_3.slv region {i} firewall.
  fields as FW_REGS_Isam64_ddr_wrap_main_0_ddrss_fw_region_0_end_address_h
{0x4C10+0x20*i} FW_REGS_Imsram32kx64e_main_3_slv_fw_region_{i}_start_address_l access per field (i=1..3) — The FW Region {i} Start Address Low Register defines the start address bits 31 to 0 for the slave Imsram32kx64e_main_3.slv region {i} firewall.
  fields as FW_REGS_Isam64_ddr_wrap_main_0_ddrss_fw_region_0_start_address_l
{0x4C18+0x20*i} FW_REGS_Imsram32kx64e_main_3_slv_fw_region_{i}_end_address_l access per field reset 0xFFF (i=1..3) — The FW Region {i} End Address Low Register defines the end address bits 31 to 0 to include for the slave Imsram32kx64e_main_3.slv region {i} firewall.
  fields as FW_REGS_Isam64_ddr_wrap_main_0_ddrss_fw_region_0_end_address_l
{0x5000+0x20*i} FW_REGS_Idmss_am64_main_0_ipcss_vbm_dst_fw_region_{i}_control access not given (i=0..7) — The FW Region {i} Control Register defines the control fields for the slave Idmss_am64_main_0.ipcss_vbm_dst region {i} firewall.
  fields as FW_REGS_Isam64_ddr_wrap_main_0_ddrss_fw_region_0_control
{0x5004+0x20*i} FW_REGS_Idmss_am64_main_0_ipcss_vbm_dst_fw_region_{i}_permission_0 (i=0..7) — The FW Region {i} Permission 0 Register defines the permissions for the slave Idmss_am64_main_0.ipcss_vbm_dst region {i} firewall.
  fields as FW_REGS_Isam64_ddr_wrap_main_0_ddrss_fw_region_0_permission_0
{0x5008+0x20*i} FW_REGS_Idmss_am64_main_0_ipcss_vbm_dst_fw_region_{i}_permission_1 (i=0..7) — The FW Region {i} Permission 1 Register defines the permissions for the slave Idmss_am64_main_0.ipcss_vbm_dst region {i} firewall.
  fields as FW_REGS_Isam64_ddr_wrap_main_0_ddrss_fw_region_0_permission_0
{0x500C+0x20*i} FW_REGS_Idmss_am64_main_0_ipcss_vbm_dst_fw_region_{i}_permission_2 (i=0..7) — The FW Region {i} Permission 2 Register defines the permissions for the slave Idmss_am64_main_0.ipcss_vbm_dst region {i} firewall.
  fields as FW_REGS_Isam64_ddr_wrap_main_0_ddrss_fw_region_0_permission_0
0x5010 FW_REGS_Idmss_am64_main_0_ipcss_vbm_dst_fw_region_0_start_address_l access per field reset 0x9B000000 — The FW Region 0 Start Address Low Register defines the start address bits 31 to 0 for the slave Idmss_am64_main_0.ipcss_vbm_dst region 0 firewall.
  fields as FW_REGS_Isam64_ddr_wrap_main_0_ddrss_fw_region_0_start_address_l
{0x5014+0x20*i} FW_REGS_Idmss_am64_main_0_ipcss_vbm_dst_fw_region_{i}_start_address_h (i=0..7) — The FW Region {i} Start Address High Register defines the start address bits 47 to 32 for the slave Idmss_am64_main_0.ipcss_vbm_dst region {i} firewall.
  [15:0] START_ADDRESS_H — Start address bits 47 to 32.
0x5018 FW_REGS_Idmss_am64_main_0_ipcss_vbm_dst_fw_region_0_end_address_l access per field reset 0x9B07FFFF — The FW Region 0 End Address Low Register defines the end address bits 31 to 0 to include for the slave Idmss_am64_main_0.ipcss_vbm_dst region 0 firewall.
  fields as FW_REGS_Isam64_ddr_wrap_main_0_ddrss_fw_region_0_end_address_l
{0x501C+0x20*i} FW_REGS_Idmss_am64_main_0_ipcss_vbm_dst_fw_region_{i}_end_address_h (i=0..7) — The FW Region {i} End Address High Register defines the end address bits 47 to 32 to include for the slave Idmss_am64_main_0.ipcss_vbm_dst region {i} firewall.
  fields as FW_REGS_Isam64_ddr_wrap_main_0_ddrss_fw_region_0_end_address_h
0x5030 FW_REGS_Idmss_am64_main_0_ipcss_vbm_dst_fw_region_1_start_address_l access per field reset 0x9C000000 — The FW Region 1 Start Address Low Register defines the start address bits 31 to 0 for the slave Idmss_am64_main_0.ipcss_vbm_dst region 1 firewall.
  fields as FW_REGS_Isam64_ddr_wrap_main_0_ddrss_fw_region_0_start_address_l
0x5038 FW_REGS_Idmss_am64_main_0_ipcss_vbm_dst_fw_region_1_end_address_l access per field reset 0x9C3FFFFF — The FW Region 1 End Address Low Register defines the end address bits 31 to 0 to include for the slave Idmss_am64_main_0.ipcss_vbm_dst region 1 firewall.
  fields as FW_REGS_Isam64_ddr_wrap_main_0_ddrss_fw_region_0_end_address_l
{0x5010+0x20*i} FW_REGS_Idmss_am64_main_0_ipcss_vbm_dst_fw_region_{i}_start_address_l access per field (i=2..7) — The FW Region {i} Start Address Low Register defines the start address bits 31 to 0 for the slave Idmss_am64_main_0.ipcss_vbm_dst region {i} firewall.
  fields as FW_REGS_Isam64_ddr_wrap_main_0_ddrss_fw_region_0_start_address_l
{0x5018+0x20*i} FW_REGS_Idmss_am64_main_0_ipcss_vbm_dst_fw_region_{i}_end_address_l access per field reset 0xFFF (i=2..7) — The FW Region {i} End Address Low Register defines the end address bits 31 to 0 to include for the slave Idmss_am64_main_0.ipcss_vbm_dst region {i} firewall.
  fields as FW_REGS_Isam64_ddr_wrap_main_0_ddrss_fw_region_0_end_address_l
{0x5400+0x20*i} FW_REGS_Iexport_vbusm_32b_slv_main2mcu_slv_fw_region_{i}_control access not given (i=0..7) — The FW Region {i} Control Register defines the control fields for the slave Iexport_vbusm_32b_slv_main2mcu.slv region {i} firewall.
  fields as FW_REGS_Isam64_ddr_wrap_main_0_ddrss_fw_region_0_control
{0x5404+0x20*i} FW_REGS_Iexport_vbusm_32b_slv_main2mcu_slv_fw_region_{i}_permission_0 (i=0..7) — The FW Region {i} Permission 0 Register defines the permissions for the slave Iexport_vbusm_32b_slv_main2mcu.slv region {i} firewall.
  fields as FW_REGS_Isam64_ddr_wrap_main_0_ddrss_fw_region_0_permission_0
{0x5408+0x20*i} FW_REGS_Iexport_vbusm_32b_slv_main2mcu_slv_fw_region_{i}_permission_1 (i=0..7) — The FW Region {i} Permission 1 Register defines the permissions for the slave Iexport_vbusm_32b_slv_main2mcu.slv region {i} firewall.
  fields as FW_REGS_Isam64_ddr_wrap_main_0_ddrss_fw_region_0_permission_0
{0x540C+0x20*i} FW_REGS_Iexport_vbusm_32b_slv_main2mcu_slv_fw_region_{i}_permission_2 (i=0..7) — The FW Region {i} Permission 2 Register defines the permissions for the slave Iexport_vbusm_32b_slv_main2mcu.slv region {i} firewall.
  fields as FW_REGS_Isam64_ddr_wrap_main_0_ddrss_fw_region_0_permission_0
0x5410 FW_REGS_Iexport_vbusm_32b_slv_main2mcu_slv_fw_region_0_start_address_l access per field reset 0x4000000 — The FW Region 0 Start Address Low Register defines the start address bits 31 to 0 for the slave Iexport_vbusm_32b_slv_main2mcu.slv region 0 firewall.
  fields as FW_REGS_Isam64_ddr_wrap_main_0_ddrss_fw_region_0_start_address_l
{0x5414+0x20*i} FW_REGS_Iexport_vbusm_32b_slv_main2mcu_slv_fw_region_{i}_start_address_h (i=0..7) — The FW Region {i} Start Address High Register defines the start address bits 47 to 32 for the slave Iexport_vbusm_32b_slv_main2mcu.slv region {i} firewall.
  [15:0] START_ADDRESS_H — Start address bits 47 to 32.
0x5418 FW_REGS_Iexport_vbusm_32b_slv_main2mcu_slv_fw_region_0_end_address_l access per field reset 0x4000FFF — The FW Region 0 End Address Low Register defines the end address bits 31 to 0 to include for the slave Iexport_vbusm_32b_slv_main2mcu.slv region 0 firewall.
  fields as FW_REGS_Isam64_ddr_wrap_main_0_ddrss_fw_region_0_end_address_l
{0x541C+0x20*i} FW_REGS_Iexport_vbusm_32b_slv_main2mcu_slv_fw_region_{i}_end_address_h (i=0..7) — The FW Region {i} End Address High Register defines the end address bits 47 to 32 to include for the slave Iexport_vbusm_32b_slv_main2mcu.slv region {i} firewall.
  fields as FW_REGS_Isam64_ddr_wrap_main_0_ddrss_fw_region_0_end_address_h
{0x5410+0x20*i} FW_REGS_Iexport_vbusm_32b_slv_main2mcu_slv_fw_region_{i}_start_address_l access per field (i=1..7) — The FW Region {i} Start Address Low Register defines the start address bits 31 to 0 for the slave Iexport_vbusm_32b_slv_main2mcu.slv region {i} firewall.
  fields as FW_REGS_Isam64_ddr_wrap_main_0_ddrss_fw_region_0_start_address_l
{0x5418+0x20*i} FW_REGS_Iexport_vbusm_32b_slv_main2mcu_slv_fw_region_{i}_end_address_l access per field reset 0xFFF (i=1..7) — The FW Region {i} End Address Low Register defines the end address bits 31 to 0 to include for the slave Iexport_vbusm_32b_slv_main2mcu.slv region {i} firewall.
  fields as FW_REGS_Isam64_ddr_wrap_main_0_ddrss_fw_region_0_end_address_l
{0x5800+0x20*i} FW_REGS_br_scrm_64b_clk2_to_scrp_misc_clk2_l0_fw_region_{i}_control access not given (i=0..15) — The FW Region {i} Control Register defines the control fields for the slave br_scrm_64b_clk2_to_scrp_misc_clk2_l0 region {i} firewall.
  fields as FW_REGS_Isam64_ddr_wrap_main_0_ddrss_fw_region_0_control
{0x5804+0x20*i} FW_REGS_br_scrm_64b_clk2_to_scrp_misc_clk2_l0_fw_region_{i}_permission_0 (i=0..15) — The FW Region {i} Permission 0 Register defines the permissions for the slave br_scrm_64b_clk2_to_scrp_misc_clk2_l0 region {i} firewall.
  fields as FW_REGS_Isam64_ddr_wrap_main_0_ddrss_fw_region_0_permission_0
{0x5808+0x20*i} FW_REGS_br_scrm_64b_clk2_to_scrp_misc_clk2_l0_fw_region_{i}_permission_1 (i=0..15) — The FW Region {i} Permission 1 Register defines the permissions for the slave br_scrm_64b_clk2_to_scrp_misc_clk2_l0 region {i} firewall.
  fields as FW_REGS_Isam64_ddr_wrap_main_0_ddrss_fw_region_0_permission_0
{0x580C+0x20*i} FW_REGS_br_scrm_64b_clk2_to_scrp_misc_clk2_l0_fw_region_{i}_permission_2 (i=0..15) — The FW Region {i} Permission 2 Register defines the permissions for the slave br_scrm_64b_clk2_to_scrp_misc_clk2_l0 region {i} firewall.
  fields as FW_REGS_Isam64_ddr_wrap_main_0_ddrss_fw_region_0_permission_0
{0x5810+0x20*i} FW_REGS_br_scrm_64b_clk2_to_scrp_misc_clk2_l0_fw_region_{i}_start_address_l access per field (i=0..15) — The FW Region {i} Start Address Low Register defines the start address bits 31 to 0 for the slave br_scrm_64b_clk2_to_scrp_misc_clk2_l0 region {i} firewall.
  fields as FW_REGS_Isam64_ddr_wrap_main_0_ddrss_fw_region_0_start_address_l
{0x5814+0x20*i} FW_REGS_br_scrm_64b_clk2_to_scrp_misc_clk2_l0_fw_region_{i}_start_address_h (i=0..15) — The FW Region {i} Start Address High Register defines the start address bits 47 to 32 for the slave br_scrm_64b_clk2_to_scrp_misc_clk2_l0 region {i} firewall.
  [15:0] START_ADDRESS_H — Start address bits 47 to 32.
{0x5818+0x20*i} FW_REGS_br_scrm_64b_clk2_to_scrp_misc_clk2_l0_fw_region_{i}_end_address_l access per field reset 0xFFF (i=0..15) — The FW Region {i} End Address Low Register defines the end address bits 31 to 0 to include for the slave br_scrm_64b_clk2_to_scrp_misc_clk2_l0 region {i} firewall.
  fields as FW_REGS_Isam64_ddr_wrap_main_0_ddrss_fw_region_0_end_address_l
{0x581C+0x20*i} FW_REGS_br_scrm_64b_clk2_to_scrp_misc_clk2_l0_fw_region_{i}_end_address_h (i=0..15) — The FW Region {i} End Address High Register defines the end address bits 47 to 32 to include for the slave br_scrm_64b_clk2_to_scrp_misc_clk2_l0 region {i} firewall.
  fields as FW_REGS_Isam64_ddr_wrap_main_0_ddrss_fw_region_0_end_address_h
{0x5C00+0x20*i} FW_REGS_Imsram32kx64e_main_6_slv_fw_region_{i}_control access not given (i=0..7) — The FW Region {i} Control Register defines the control fields for the slave Imsram32kx64e_main_6.slv region {i} firewall.
  fields as FW_REGS_Isam64_ddr_wrap_main_0_ddrss_fw_region_0_control
{0x5C04+0x20*i} FW_REGS_Imsram32kx64e_main_6_slv_fw_region_{i}_permission_0 (i=0..7) — The FW Region {i} Permission 0 Register defines the permissions for the slave Imsram32kx64e_main_6.slv region {i} firewall.
  fields as FW_REGS_Isam64_ddr_wrap_main_0_ddrss_fw_region_0_permission_0
{0x5C08+0x20*i} FW_REGS_Imsram32kx64e_main_6_slv_fw_region_{i}_permission_1 (i=0..7) — The FW Region {i} Permission 1 Register defines the permissions for the slave Imsram32kx64e_main_6.slv region {i} firewall.
  fields as FW_REGS_Isam64_ddr_wrap_main_0_ddrss_fw_region_0_permission_0
{0x5C0C+0x20*i} FW_REGS_Imsram32kx64e_main_6_slv_fw_region_{i}_permission_2 (i=0..7) — The FW Region {i} Permission 2 Register defines the permissions for the slave Imsram32kx64e_main_6.slv region {i} firewall.
  fields as FW_REGS_Isam64_ddr_wrap_main_0_ddrss_fw_region_0_permission_0
0x5C10 FW_REGS_Imsram32kx64e_main_6_slv_fw_region_0_start_address_l access per field reset 0x440A0000 — The FW Region 0 Start Address Low Register defines the start address bits 31 to 0 for the slave Imsram32kx64e_main_6.slv region 0 firewall.
  fields as FW_REGS_Isam64_ddr_wrap_main_0_ddrss_fw_region_0_start_address_l
{0x5C14+0x20*i} FW_REGS_Imsram32kx64e_main_6_slv_fw_region_{i}_start_address_h (i=0..7) — The FW Region {i} Start Address High Register defines the start address bits 47 to 32 for the slave Imsram32kx64e_main_6.slv region {i} firewall.
  [15:0] START_ADDRESS_H — Start address bits 47 to 32.
0x5C18 FW_REGS_Imsram32kx64e_main_6_slv_fw_region_0_end_address_l access per field reset 0x440DFFFF — The FW Region 0 End Address Low Register defines the end address bits 31 to 0 to include for the slave Imsram32kx64e_main_6.slv region 0 firewall.
  fields as FW_REGS_Isam64_ddr_wrap_main_0_ddrss_fw_region_0_end_address_l
{0x5C1C+0x20*i} FW_REGS_Imsram32kx64e_main_6_slv_fw_region_{i}_end_address_h (i=0..7) — The FW Region {i} End Address High Register defines the end address bits 47 to 32 to include for the slave Imsram32kx64e_main_6.slv region {i} firewall.
  fields as FW_REGS_Isam64_ddr_wrap_main_0_ddrss_fw_region_0_end_address_h
{0x5C10+0x20*i} FW_REGS_Imsram32kx64e_main_6_slv_fw_region_{i}_start_address_l access per field (i=1..7) — The FW Region {i} Start Address Low Register defines the start address bits 31 to 0 for the slave Imsram32kx64e_main_6.slv region {i} firewall.
  fields as FW_REGS_Isam64_ddr_wrap_main_0_ddrss_fw_region_0_start_address_l
{0x5C18+0x20*i} FW_REGS_Imsram32kx64e_main_6_slv_fw_region_{i}_end_address_l access per field reset 0xFFF (i=1..7) — The FW Region {i} End Address Low Register defines the end address bits 31 to 0 to include for the slave Imsram32kx64e_main_6.slv region {i} firewall.
  fields as FW_REGS_Isam64_ddr_wrap_main_0_ddrss_fw_region_0_end_address_l
{0x6000+0x20*i} FW_REGS_Imsram32kx64e_main_7_slv_fw_region_{i}_control access not given (i=0..7) — The FW Region {i} Control Register defines the control fields for the slave Imsram32kx64e_main_7.slv region {i} firewall.
  fields as FW_REGS_Isam64_ddr_wrap_main_0_ddrss_fw_region_0_control
{0x6004+0x20*i} FW_REGS_Imsram32kx64e_main_7_slv_fw_region_{i}_permission_0 (i=0..7) — The FW Region {i} Permission 0 Register defines the permissions for the slave Imsram32kx64e_main_7.slv region {i} firewall.
  fields as FW_REGS_Isam64_ddr_wrap_main_0_ddrss_fw_region_0_permission_0
{0x6008+0x20*i} FW_REGS_Imsram32kx64e_main_7_slv_fw_region_{i}_permission_1 (i=0..7) — The FW Region {i} Permission 1 Register defines the permissions for the slave Imsram32kx64e_main_7.slv region {i} firewall.
  fields as FW_REGS_Isam64_ddr_wrap_main_0_ddrss_fw_region_0_permission_0
{0x600C+0x20*i} FW_REGS_Imsram32kx64e_main_7_slv_fw_region_{i}_permission_2 (i=0..7) — The FW Region {i} Permission 2 Register defines the permissions for the slave Imsram32kx64e_main_7.slv region {i} firewall.
  fields as FW_REGS_Isam64_ddr_wrap_main_0_ddrss_fw_region_0_permission_0
0x6010 FW_REGS_Imsram32kx64e_main_7_slv_fw_region_0_start_address_l access per field reset 0x701C0000 — The FW Region 0 Start Address Low Register defines the start address bits 31 to 0 for the slave Imsram32kx64e_main_7.slv region 0 firewall.
  fields as FW_REGS_Isam64_ddr_wrap_main_0_ddrss_fw_region_0_start_address_l
{0x6014+0x20*i} FW_REGS_Imsram32kx64e_main_7_slv_fw_region_{i}_start_address_h (i=0..7) — The FW Region {i} Start Address High Register defines the start address bits 47 to 32 for the slave Imsram32kx64e_main_7.slv region {i} firewall.
  [15:0] START_ADDRESS_H — Start address bits 47 to 32.
0x6018 FW_REGS_Imsram32kx64e_main_7_slv_fw_region_0_end_address_l access per field reset 0x701FFFFF — The FW Region 0 End Address Low Register defines the end address bits 31 to 0 to include for the slave Imsram32kx64e_main_7.slv region 0 firewall.
  fields as FW_REGS_Isam64_ddr_wrap_main_0_ddrss_fw_region_0_end_address_l
{0x601C+0x20*i} FW_REGS_Imsram32kx64e_main_7_slv_fw_region_{i}_end_address_h (i=0..7) — The FW Region {i} End Address High Register defines the end address bits 47 to 32 to include for the slave Imsram32kx64e_main_7.slv region {i} firewall.
  fields as FW_REGS_Isam64_ddr_wrap_main_0_ddrss_fw_region_0_end_address_h
{0x6010+0x20*i} FW_REGS_Imsram32kx64e_main_7_slv_fw_region_{i}_start_address_l access per field (i=1..7) — The FW Region {i} Start Address Low Register defines the start address bits 31 to 0 for the slave Imsram32kx64e_main_7.slv region {i} firewall.
  fields as FW_REGS_Isam64_ddr_wrap_main_0_ddrss_fw_region_0_start_address_l
{0x6018+0x20*i} FW_REGS_Imsram32kx64e_main_7_slv_fw_region_{i}_end_address_l access per field reset 0xFFF (i=1..7) — The FW Region {i} End Address Low Register defines the end address bits 31 to 0 to include for the slave Imsram32kx64e_main_7.slv region {i} firewall.
  fields as FW_REGS_Isam64_ddr_wrap_main_0_ddrss_fw_region_0_end_address_l
